# ESP32S31_RADIO register map
Vendor: Espressif; Series: ESP32-S31; File version: 3.52
Registers are 32-bit, read-write, no defined reset value unless marked. A register's access mark holds for its fields unless they carry their own. Offsets are from the block's base; [hi:lo] are bit positions.

## WIFI_MAC_RX_STATISTICS — Sparse RX hardware statistics decoded by complete dbg_read_rx_count. Ten-bit and sixteen-bit masks, the signed CFO transform and every register address below follow the complete instruction body and its pinned format string. Open HE HIL observed coherent MPDU/end/data, CFO, FCS, power-drop, HT-SIG, HE-SIG-A and interrupt counts while all buffer/FIFO/TKIP counters remained zero.
Base 0x2010430C
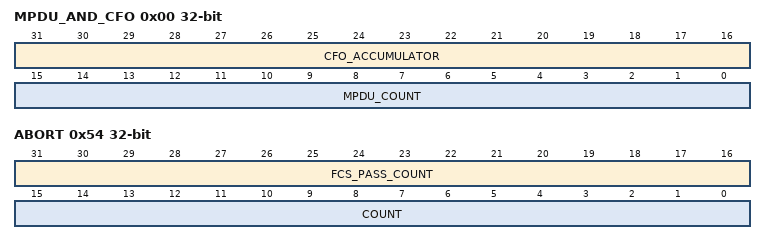
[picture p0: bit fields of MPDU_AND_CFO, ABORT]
0x00 MPDU_AND_CFO ro — Project-assigned name. WDEVRX_MPDU in bits 15:0. The blob sign-extends bits 31:16 and multiplies by 40 to print WDEVRX_CFO.
  [31:16] CFO_ACCUMULATOR — Project-assigned name.
  [15:0] MPDU_COUNT — Project-assigned name.
0x04 BRX_ERROR_AGC ro — Project-assigned name.
  [9:0] COUNT
0x08 BRX_ERROR ro — Project-assigned name.
  [9:0] COUNT
0x0C NRX_ERROR ro — Project-assigned name.
  [9:0] COUNT
0x10 NRX_ERROR_ABORT ro — Project-assigned name.
  [9:0] COUNT
0x14 NRX_ERROR_AGC_EXIT ro — Project-assigned name.
  [9:0] COUNT
0x18 NRX_ERROR_BASEBAND_OFF ro — Project-assigned name.
  [9:0] COUNT
0x1C NRX_ERROR_FDM_WATCHDOG ro — Project-assigned name.
  [9:0] COUNT
0x20 NRX_ERROR_POWER_DROP ro — Project-assigned name.
  [9:0] COUNT
0x24 NRX_ERROR_RESTART ro — Project-assigned name.
  [9:0] COUNT
0x28 NRX_ERROR_SERVICE ro — Project-assigned name.
  [9:0] COUNT
0x2C NRX_ERROR_TX_OVER ro — Project-assigned name.
  [9:0] COUNT
0x30 NRX_HE_UNSUPPORTED ro — Project-assigned name.
  [9:0] COUNT
0x34 NRX_HE_SIG_A_CRC ro — Project-assigned name.
  [9:0] COUNT
0x38 NRX_HE_FORMAT ro — Project-assigned name.
  [9:0] COUNT
0x3C NRX_HE_SIG_B_ERROR ro — Project-assigned name.
  [15:0] COUNT
0x40 NRX_HT_SIG_ERROR ro — Project-assigned name.
  [9:0] COUNT
0x44 NRX_UNSUPPORTED ro — Project-assigned name.
  [9:0] COUNT
0x50 SIGNAL_FIELD ro — Project-assigned name. WDEVRX_SF.
  [15:0] COUNT — Project-assigned name.
0x54 ABORT ro — Project-assigned name.
  [31:16] FCS_PASS_COUNT — Project-assigned name.
  [15:0] COUNT — Project-assigned name.
0x58 FCS_ERROR ro — Project-assigned name.
  [15:0] COUNT
0x5C FIFO_OVERFLOW ro — Project-assigned name.
  [15:0] COUNT
0x60 BUFFER_FULL ro — Project-assigned name.
  [15:0] COUNT
0x64 OTHER_UNICAST ro — Project-assigned name.
  [15:0] COUNT
0x68 TKIP_ERROR ro — Project-assigned name.
  [15:0] COUNT
0x6C SAME_BM_ERROR ro — Project-assigned name.
  [15:0] COUNT
0x70 ACK_INTERRUPT ro — Project-assigned name.
  [15:0] COUNT
0x74 RTS_INTERRUPT ro — Project-assigned name.
  [15:0] COUNT
0x78 CTS_INTERRUPT ro — Project-assigned name. Complete dbg_lmac_hw_statis_dump prints the full word at 0x20104384 as cts_int. Its internal field width is not inferred.
  [31:0] VALUE — Project-assigned name.
0x7C DATA_SUCCESS ro — Project-assigned name.
  [15:0] COUNT
0x80 END ro — Project-assigned name.
  [15:0] COUNT
0x84 BT_BLOCK_ERROR ro — Project-assigned name.
  [15:0] COUNT
0x88 FREQUENCY_HOP_ERROR ro — Project-assigned name.
  [15:0] COUNT
0x8C LAST_UNMATCHED_ERROR ro — Project-assigned name.
  [15:0] COUNT
0x90 TRIGGER ro — Project-assigned name. Complete dbg_lmac_hw_statis_dump prints the full word at 0x2010439c as trigger. This is a separate hardware-statistics observation from the decoded HE Trigger RX counter at 0x20104dbc.
  [31:0] VALUE — Project-assigned name.

## WIFI_MAC_TX_STATISTICS — Complete libpp.a[pp_debug.o]::dbg_lmac_hw_statis_dump reads these four consecutive words and prints them as txrts, txcts, track and trcts. It then reads the already canonical RX_TX_HANG/PANIC words at 0x20104e18/1c under its shorter txhung/panic labels. The blob applies no masks; the SVD therefore preserves each word without inventing subfields.
Base 0x20104E08
0x00 TX_RTS ro — Project-assigned name.
  [31:0] VALUE
0x04 TX_CTS ro — Project-assigned name.
  [31:0] VALUE
0x08 TRACK ro — Project-assigned name.
  [31:0] VALUE
0x0C TRCTS ro — Project-assigned name. The abbreviated blob label is retained verbatim; its expansion is not yet proven.
  [31:0] VALUE — Project-assigned name.
